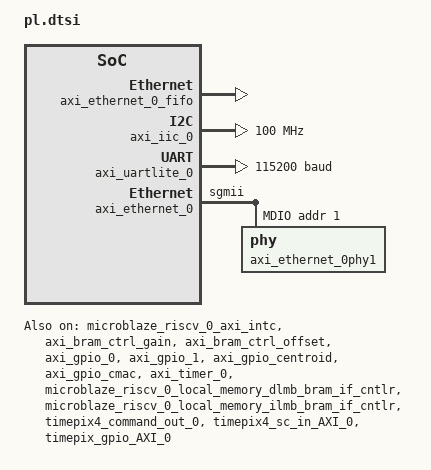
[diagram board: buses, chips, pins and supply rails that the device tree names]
/ {
	cpus_microblaze_riscv_0: cpus_microblaze_riscv@0 {
		#cpu-mask-cells = <1>;
		compatible = "cpus,cluster";
		#address-cells = <1>;
		#size-cells = <0>;
		microblaze_riscv_0: cpu@0 {
			xlnx,d-axi = <1>;
			xlnx,pmp-entries = <0>;
			xlnx,temporal-depth = <0>;
			xlnx,dcache-force-tag-lutram = <0>;
			reg = <0x0>;
			xlnx,interrupt-is-edge = <0>;
			xlnx,use-mmu = <0>;
			xlnx,dc-axi-mon = <0>;
			xlnx,debug-trace-async-reset = <0>;
			xlnx,part = "xcvu37p-fsvh2892-2l-e";
			xlnx,use-config-reset = <0>;
			xlnx,family = "virtexuplusHBM";
			xlnx,use-sleep = <0>;
			xlnx,d-lmb = <1>;
			xlnx,enable-discrete-ports = <0>;
			xlnx,debug-interface = <0>;
			xlnx,use-ext-brk = <0>;
			xlnx,debug-enabled = <1>;
			xlnx,daddr-size = <32>;
			xlnx,use-extended-fsl-instr = <0>;
			xlnx,branch-target-cache-size = <0>;
			bus-handle = <&amba_pl>;
			xlnx,pmp-addr0 = <0x0>;
			xlnx,pmp-addr1 = <0x0>;
			xlnx,pmp-addr2 = <0x0>;
			xlnx,pmp-addr3 = <0x0>;
			xlnx,pmp-addr4 = <0x0>;
			xlnx,edk-special = "microblaze_riscv";
			xlnx,use-dcache = <0>;
			xlnx,pmp-addr5 = <0x0>;
			xlnx,use-muldiv = <2>;
			xlnx,pmp-addr6 = <0x0>;
			xlnx,use-axi-dp-ext-addr = <0>;
			xlnx,pmp-addr7 = <0x0>;
			xlnx,pmp-addr8 = <0x0>;
			xlnx,pmp-addr9 = <0x0>;
			xlnx,i-axi = <0>;
			xlnx,icache-streams = <0>;
			xlnx,i-lmb-has-prot = <0>;
			xlnx,num-sync-ff-dbg-clk = <1>;
			xlnx,icache-byte-size = <4096>;
			xlnx,pmp-addr10 = <0x0>;
			d-cache-size = <4096>;
			xlnx,pmp-addr11 = <0x0>;
			xlnx,pmp-addr12 = <0x0>;
			xlnx,pmp-addr13 = <0x0>;
			xlnx,pmp-addr14 = <0x0>;
			xlnx,pmp-addr15 = <0x0>;
			xlnx,avoid-primitives = <0>;
			xlnx,pmp-addr16 = <0x0>;
			xlnx,pmp-addr17 = <0x0>;
			xlnx,pmp-addr18 = <0x0>;
			xlnx,pdaddr-size = <32>;
			xlnx,pmp-addr19 = <0x0>;
			xlnx,pmp-addr20 = <0x0>;
			xlnx,pmp-addr21 = <0x0>;
			xlnx,i-lmb = <1>;
			xlnx,pmp-addr22 = <0x0>;
			xlnx,lmb-data-size = <32>;
			xlnx,lockstep-select = <0>;
			xlnx,pmp-addr23 = <0x0>;
			timebase-frequency = <100000000>;
			xlnx,pmp-addr24 = <0x0>;
			xlnx,dcache-data-width = <0>;
			xlnx,icache-force-tag-lutram = <0>;
			xlnx,pmp-addr25 = <0x0>;
			xlnx,pmp-addr26 = <0x0>;
			xlnx,use-branch-target-cache = <0>;
			xlnx,pmp-addr27 = <0x0>;
			xlnx,number-of-pc-brk = <1>;
			xlnx,pmp-addr28 = <0x0>;
			xlnx,imprecise-exceptions = <0>;
			xlnx,pmp-addr29 = <0x0>;
			xlnx,pmp-addr30 = <0x0>;
			xlnx,pmp-addr31 = <0x0>;
			xlnx,pmp-addr32 = <0x0>;
			model = "microblaze_riscv,1.0";
			xlnx,pmp-addr33 = <0x0>;
			xlnx,pmp-addr34 = <0x0>;
			xlnx,pmp-addr35 = <0x0>;
			xlnx,pmp-addr36 = <0x0>;
			d-cache-highaddr = <0x3fffffff>;
			xlnx,optimization = <1>;
			xlnx,pmp-addr37 = <0x0>;
			xlnx,pmp-addr38 = <0x0>;
			xlnx,pmp-addr39 = <0x0>;
			xlnx,pmp-addr40 = <0x0>;
			xlnx,pmp-addr41 = <0x0>;
			xlnx,d-lmb-mon = <0>;
			xlnx,pmp-addr42 = <0x0>;
			xlnx,pmp-addr43 = <0x0>;
			xlnx,pmp-addr44 = <0x0>;
			xlnx,pmp-addr45 = <0x0>;
			xlnx,pmp-addr46 = <0x0>;
			xlnx,pmp-addr47 = <0x0>;
			xlnx,pmp-addr48 = <0x0>;
			xlnx,fault-tolerant = <0>;
			xlnx,pmp-addr49 = <0x0>;
			xlnx,pmp-addr50 = <0x0>;
			xlnx,pmp-addr51 = <0x0>;
			xlnx,pmp-enhancements = <0>;
			d-cache-line-size = <16>;
			xlnx,mmu-privileged-instr = <0>;
			xlnx,pmp-addr52 = <0x0>;
			clock-frequency = <100000000>;
			xlnx,pmp-addr53 = <0x0>;
			xlnx,pmp-addr54 = <0x0>;
			xlnx,pmp-addr55 = <0x0>;
			xlnx,i-lmb-protocol = <0>;
			xlnx,pmp-addr56 = <0x0>;
			xlnx,pmp-addr57 = <0x0>;
			xlnx,dp-axi-mon = <0>;
			xlnx,pmp-addr58 = <0x0>;
			xlnx,pmp-addr59 = <0x0>;
			xlnx,pmp-addr60 = <0x0>;
			xlnx,pmp-addr61 = <0x0>;
			xlnx,pmp-addr62 = <0x0>;
			xlnx,pmp-addr63 = <0x0>;
			xlnx,debug-external-trace = <0>;
			xlnx,addr-size = <32>;
			xlnx,debug-num-progbuf = <2>;
			xlnx,debug-event-counters = <0>;
			xlnx,edk-iptype = "PROCESSOR";
			xlnx,debug-latency-counters = <0>;
			xlnx,interconnect = <2>;
			xlnx,edge-is-positive = <1>;
			xlnx,use-icache = <0>;
			xlnx,async-wakeup = <3>;
			xlnx,s-axi = <0>;
			xlnx,use-ext-nm-brk = <0>;
			xlnx,ic-axi-mon = <0>;
			xlnx,archid = <0x1>;
			xlnx,num-sync-ff-clk-irq = <1>;
			xlnx,freq = <100000000>;
			xlnx,lockstep-master = <0>;
			xlnx,pmp-cfg0 = <0x0>;
			xlnx,pmp-cfg1 = <0x0>;
			xlnx,iaddr-size = <32>;
			xlnx,interrupt-mon = <0>;
			xlnx,pmp-cfg2 = <0x0>;
			xlnx,number-of-wr-addr-brk = <0>;
			xlnx,pmp-cfg3 = <0x0>;
			xlnx,pmp-cfg4 = <0x0>;
			xlnx,use-interrupt = <2>;
			xlnx,pmp-cfg5 = <0x0>;
			xlnx,async-interrupt = <1>;
			xlnx,pc-width = <20>;
			xlnx,pmp-cfg6 = <0x0>;
			xlnx,icache-victims = <0>;
			xlnx,pmp-cfg7 = <0x0>;
			xlnx,pmp-cfg8 = <0x0>;
			xlnx,pmp-cfg9 = <0x0>;
			xlnx,use-bitman-a = <0>;
			xlnx,use-bitman-b = <0>;
			xlnx,use-bitman-c = <0>;
			xlnx,i-lmb-mon = <0>;
			xlnx,dcache-byte-size = <4096>;
			xlnx,data-size = <32>;
			compatible = "xlnx,microblaze-riscv-1.0" , "xlnx,microblaze_riscv";
			xlnx,pmp-debug-inhibit = <0x0>;
			xlnx,use-sstc = <1>;
			xlnx,fsl-exception = <0>;
			xlnx,dcache-use-writeback = <0>;
			device_type = "cpu";
			xlnx,impid = <0x1>;
			xlnx,use-bitman-s = <0>;
			xlnx,base-vectors = <0x0>;
			xlnx,icache-line-len = <4>;
			xlnx,d-lmb-has-prot = <0>;
			xlnx,use-barrel = <1>;
			xlnx,misaligned-exceptions = <0>;
			xlnx,piaddr-size = <32>;
			xlnx,use-bitman = <0>;
			xlnx,dcache-line-len = <4>;
			xlnx,num-sync-ff-clk = <2>;
			xlnx,memory-ip-list = "microblaze_riscv_0_local_memory_ilmb_bram_if_cntlr_memory" , "microblaze_riscv_0_local_memory_dlmb_bram_if_cntlr_memory";
			xlnx,number-of-rd-addr-brk = <0>;
			xlnx,use-counters = <1>;
			xlnx,lockstep-slave = <0>;
			interrupt-handle = <&microblaze_riscv_0_axi_intc>;
			xlnx,pmp-cfg10 = <0x0>;
			xlnx,pmp-cfg11 = <0x0>;
			xlnx,debug-profile-size = <0>;
			xlnx,pmp-cfg12 = <0x0>;
			xlnx,pmp-cfg13 = <0x0>;
			xlnx,pmp-cfg14 = <0x0>;
			xlnx,pmp-cfg15 = <0x0>;
			xlnx,debug-counter-width = <64>;
			xlnx,icache-data-width = <0>;
			xlnx,ip-name = "microblaze_riscv";
			xlnx,ip-axi-mon = <0>;
			xlnx,d-lmb-protocol = <0>;
			xlnx,trace = <0>;
			xlnx,ill-instr-exception = <1>;
			xlnx,debug-trace-size = <8192>;
			xlnx,pmp-granularity = <3>;
			xlnx,num-sync-ff-dbg-trace-clk = <2>;
			xlnx,ecc-use-ce-exception = <0>;
			xlnx,num-sync-ff-clk-debug = <2>;
			xlnx,use-atomic = <0>;
			xlnx,g-template-list = <1>;
			xlnx,trap-enhancement = <0>;
			xlnx,hartid = <0x0>;
			xlnx,use-fpu = <0>;
			xlnx,use-non-secure = <0>;
			d-cache-baseaddr = <0x0>;
			xlnx,use-compression = <1>;
			xlnx,instr-size = <32>;
			xlnx,fsl-links = <0>;
			xlnx,dcache-victims = <0>;
			xlnx,pmp-read-only = <0x0>;
		};
	};
	clock: clocks {
		#address-cells = <1>;
		#size-cells = <0>;
		clk_cpu_0: clk_cpu@0 {
			compatible = "fixed-clock";
			reg = <0>;
			clock-frequency = <100000000>;
			clock-output-names = "clk_cpu";
			#clock-cells = <0>;
		};
		clk_bus_0: clk_bus_0@1 {
			compatible = "fixed-clock";
			reg = <1>;
			clock-frequency = <100000000>;
			clock-output-names = "clk_bus_0";
			#clock-cells = <0>;
		};
	};
	amba_pl: amba_pl {
		ranges;
		compatible = "simple-bus";
		#address-cells = <1>;
		#size-cells = <1>;
		microblaze_riscv_0_axi_intc: interrupt-controller@41200000 {
			#interrupt-cells = <2>;
			xlnx,sense-of-irq-edge-type = "Rising";
			xlnx,edk-special = "INTR_CTRL";
			xlnx,kind-of-intr = <0x0>;
			xlnx,kind-of-edge = <0xffffffff>;
			xlnx,irq-is-level = <1>;
			xlnx,has-ivr = <1>;
			compatible = "xlnx,axi-intc-4.1" , "xlnx,xps-intc-1.00.a";
			xlnx,disable-synchronizers = <1>;
			xlnx,kind-of-lvl = <0xffffffff>;
			xlnx,ivar-reset-value = <0x10>;
			xlnx,irq-active = <0x1>;
			xlnx,en-cascade-mode = <0>;
			xlnx,ip-name = "axi_intc";
			xlnx,has-ilr = <0>;
			reg = <0x41200000 0x10000>;
			xlnx,addr-width = <0x20>;
			xlnx,s-axi-aclk-freq-mhz = <100>;
			xlnx,num-sw-intr = <0>;
			xlnx,irq-connection = <0>;
			xlnx,num-intr-inputs = <0x4>;
			xlnx,has-sie = <1>;
			xlnx,enable-async = <0>;
			xlnx,has-cie = <1>;
			xlnx,num-sync-ff = <2>;
			xlnx,edk-iptype = "PERIPHERAL";
			xlnx,mb-clk-not-connected = <1>;
			xlnx,has-ipr = <1>;
			xlnx,sense-of-irq-level-type = "Active_High";
			xlnx,cascade-master = <0>;
			xlnx,processor-clk-freq-mhz = <100>;
			status = "okay";
			xlnx,is-fast = <0x1>;
			xlnx,has-fast = <1>;
			xlnx,ivar-rst-val = <0x10>;
			interrupt-controller;
			xlnx,async-intr = <0xfffffff4>;
			xlnx,name = "microblaze_riscv_0_axi_intc";
		};
		axi_bram_ctrl_gain: axi_bram_ctrl_gain@c0000000 {
			xlnx,protocol = "AXI4";
			xlnx,edk-special = "BRAM_CTRL";
			compatible = "xlnx,axi-bram-ctrl-4.1" , "xlnx,axi-bram-ctrl";
			xlnx,ecc-onoff-reset-value = <0>;
			xlnx,ecc-type = <0>;
			xlnx,rd-cmd-optimization = <0>;
			xlnx,memory-depth = <131072>;
			xlnx,use-ecc = <0>;
			xlnx,fault-inject = <0>;
			xlnx,ip-name = "axi_bram_ctrl";
			reg = <0xc0000000 0x80000>;
			xlnx,bmg-instance = "EXTERNAL";
			xlnx,s-axi-ctrl-addr-width = <32>;
			xlnx,read-latency = <1>;
			xlnx,id-width = <0>;
			xlnx,s-axi-supports-narrow-burst = <0>;
			xlnx,supports-narrow-burst = <0>;
			xlnx,single-port-bram = <1>;
			xlnx,ecc = <0>;
			xlnx,edk-iptype = "PERIPHERAL";
			status = "okay";
			xlnx,data-width = <32>;
			xlnx,bram-addr-width = <17>;
			xlnx,bram-inst-mode = "EXTERNAL";
			xlnx,s-axi-ctrl-data-width = <32>;
			xlnx,mem-depth = <131072>;
			xlnx,s-axi-id-width = <1>;
			xlnx,name = "axi_bram_ctrl_gain";
		};
		axi_bram_ctrl_offset: axi_bram_ctrl_offset@c2000000 {
			xlnx,protocol = "AXI4";
			xlnx,edk-special = "BRAM_CTRL";
			compatible = "xlnx,axi-bram-ctrl-4.1" , "xlnx,axi-bram-ctrl";
			xlnx,ecc-onoff-reset-value = <0>;
			xlnx,ecc-type = <0>;
			xlnx,rd-cmd-optimization = <0>;
			xlnx,memory-depth = <131072>;
			xlnx,use-ecc = <0>;
			xlnx,fault-inject = <0>;
			xlnx,ip-name = "axi_bram_ctrl";
			reg = <0xc2000000 0x80000>;
			xlnx,bmg-instance = "EXTERNAL";
			xlnx,s-axi-ctrl-addr-width = <32>;
			xlnx,read-latency = <1>;
			xlnx,id-width = <0>;
			xlnx,s-axi-supports-narrow-burst = <0>;
			xlnx,supports-narrow-burst = <0>;
			xlnx,single-port-bram = <1>;
			xlnx,ecc = <0>;
			xlnx,edk-iptype = "PERIPHERAL";
			status = "okay";
			xlnx,data-width = <32>;
			xlnx,bram-addr-width = <17>;
			xlnx,bram-inst-mode = "EXTERNAL";
			xlnx,s-axi-ctrl-data-width = <32>;
			xlnx,mem-depth = <131072>;
			xlnx,s-axi-id-width = <1>;
			xlnx,name = "axi_bram_ctrl_offset";
		};
		axi_ethernet_0_fifo: axi_fifo_mm_s@44a00000 {
			interrupts = < 1 2 >;
			xlnx,select-xpm = <0>;
			xlnx,axis-tuser-width = <4>;
			compatible = "xlnx,axi-fifo-mm-s-4.3" , "xlnx,axi-fifo-mm-s";
			xlnx,use-rx-data = <1>;
			xlnx,tx-cascade-height = <0>;
			xlnx,rx-has-ecc-err-inject = <0>;
			xlnx,axi-str-txc-protocol = "XIL_AXI_STREAM_ETH_CTRL";
			xlnx,use-tx-data = <1>;
			xlnx,tx-has-ecc-err-inject = <0>;
			xlnx,rx-fifo-depth = <4096>;
			interrupt-parent = <&microblaze_riscv_0_axi_intc>;
			xlnx,has-axis-tuser = <0>;
			xlnx,tx-fifo-depth = <4096>;
			xlnx,rx-fifo-pe-threshold = <10>;
			xlnx,data-interface-type = <0>;
			xlnx,ip-name = "axi_fifo_mm_s";
			xlnx,use-tx-ctrl = <1>;
			xlnx,rx-fifo-pf-threshold = <4000>;
			xlnx,axis-tid-width = <4>;
			reg = <0x44a00000 0x10000>;
			xlnx,tx-fifo-pe-threshold = <10>;
			xlnx,tx-fifo-pf-threshold = <4000>;
			xlnx,s-axi4-data-width = <32>;
			xlnx,has-axis-tstrb = <0>;
			xlnx,axi-str-rxd-protocol = "XIL_AXI_STREAM_ETH_DATA";
			xlnx,use-rx-cut-through = <0>;
			xlnx,axi-str-rxd-tdata-width = <32>;
			xlnx,axis-tdest-width = <4>;
			xlnx,edk-iptype = "PERIPHERAL";
			xlnx,has-axis-tkeep = <1>;
			xlnx,has-axis-tid = <0>;
			xlnx,axi-str-txc-tdata-width = <32>;
			xlnx,axi-str-txd-protocol = "XIL_AXI_STREAM_ETH_DATA";
			xlnx,use-tx-cut-through = <0>;
			xlnx,axi-str-txd-tdata-width = <32>;
			xlnx,rx-enable-ecc = <0>;
			status = "okay";
			xlnx,has-axis-tdest = <0>;
			interrupt-names = "interrupt";
			xlnx,tx-enable-ecc = <0>;
			xlnx,s-axi-id-width = <4>;
			xlnx,rx-cascade-height = <0>;
			xlnx,name = "axi_ethernet_0_fifo";
		};
		axi_gpio_0: gpio@40020000 {
			xlnx,gpio-board-interface = "led_8bits";
			compatible = "xlnx,axi-gpio-2.0" , "xlnx,xps-gpio-1.00.a";
			xlnx,all-outputs = <1>;
			#gpio-cells = <2>;
			xlnx,gpio-width = <8>;
			clock-frequency = <100000000>;
			xlnx,dout-default = <0x0>;
			xlnx,is-dual = <1>;
			xlnx,ip-name = "axi_gpio";
			xlnx,tri-default-2 = <0xffffffff>;
			reg = <0x40020000 0x10000>;
			xlnx,all-inputs-2 = <0>;
			clocks = <&clk_bus_0>;
			xlnx,all-outputs-2 = <1>;
			gpio-controller;
			xlnx,interrupt-present = <0>;
			xlnx,gpio2-board-interface = "Custom";
			xlnx,edk-iptype = "PERIPHERAL";
			xlnx,dout-default-2 = <0x0>;
			status = "okay";
			xlnx,gpio2-width = <4>;
			clock-names = "s_axi_aclk";
			xlnx,use-board-flow;
			xlnx,tri-default = <0xffffffff>;
			xlnx,name = "axi_gpio_0";
			xlnx,all-inputs = <0>;
		};
		axi_gpio_1: gpio@40010000 {
			xlnx,gpio-board-interface = "Custom";
			compatible = "xlnx,axi-gpio-2.0" , "xlnx,xps-gpio-1.00.a";
			xlnx,all-outputs = <0>;
			#gpio-cells = <2>;
			xlnx,gpio-width = <32>;
			clock-frequency = <100000000>;
			xlnx,dout-default = <0x0>;
			xlnx,is-dual = <1>;
			xlnx,ip-name = "axi_gpio";
			xlnx,tri-default-2 = <0xffffffff>;
			reg = <0x40010000 0x10000>;
			xlnx,all-inputs-2 = <0>;
			clocks = <&clk_bus_0>;
			xlnx,all-outputs-2 = <0>;
			gpio-controller;
			xlnx,interrupt-present = <0>;
			xlnx,gpio2-board-interface = "Custom";
			xlnx,edk-iptype = "PERIPHERAL";
			xlnx,dout-default-2 = <0x0>;
			status = "okay";
			xlnx,gpio2-width = <32>;
			clock-names = "s_axi_aclk";
			xlnx,tri-default = <0xffffffff>;
			xlnx,name = "axi_gpio_1";
			xlnx,all-inputs = <0>;
		};
		axi_gpio_centroid: gpio@40030000 {
			xlnx,gpio-board-interface = "Custom";
			compatible = "xlnx,axi-gpio-2.0" , "xlnx,xps-gpio-1.00.a";
			xlnx,all-outputs = <1>;
			#gpio-cells = <2>;
			xlnx,gpio-width = <32>;
			clock-frequency = <100000000>;
			xlnx,dout-default = <0x0>;
			xlnx,is-dual = <1>;
			xlnx,ip-name = "axi_gpio";
			xlnx,tri-default-2 = <0xffffffff>;
			reg = <0x40030000 0x10000>;
			xlnx,all-inputs-2 = <0>;
			clocks = <&clk_bus_0>;
			xlnx,all-outputs-2 = <1>;
			gpio-controller;
			xlnx,interrupt-present = <0>;
			xlnx,gpio2-board-interface = "Custom";
			xlnx,edk-iptype = "PERIPHERAL";
			xlnx,dout-default-2 = <0x0>;
			status = "okay";
			xlnx,gpio2-width = <32>;
			clock-names = "s_axi_aclk";
			xlnx,tri-default = <0xffffffff>;
			xlnx,name = "axi_gpio_centroid";
			xlnx,all-inputs = <0>;
		};
		axi_gpio_cmac: gpio@40000000 {
			xlnx,gpio-board-interface = "Custom";
			compatible = "xlnx,axi-gpio-2.0" , "xlnx,xps-gpio-1.00.a";
			xlnx,all-outputs = <0>;
			#gpio-cells = <2>;
			xlnx,gpio-width = <32>;
			clock-frequency = <100000000>;
			xlnx,dout-default = <0x0>;
			xlnx,is-dual = <0>;
			xlnx,ip-name = "axi_gpio";
			xlnx,tri-default-2 = <0xffffffff>;
			reg = <0x40000000 0x10000>;
			xlnx,all-inputs-2 = <0>;
			clocks = <&clk_bus_0>;
			xlnx,all-outputs-2 = <0>;
			gpio-controller;
			xlnx,interrupt-present = <0>;
			xlnx,gpio2-board-interface = "Custom";
			xlnx,edk-iptype = "PERIPHERAL";
			xlnx,dout-default-2 = <0x0>;
			status = "okay";
			xlnx,gpio2-width = <32>;
			clock-names = "s_axi_aclk";
			xlnx,tri-default = <0xffffffff>;
			xlnx,name = "axi_gpio_cmac";
			xlnx,all-inputs = <0>;
		};
		axi_iic_0: i2c@40800000 {
			xlnx,iic-freq-khz = <100>;
			compatible = "xlnx,axi-iic-2.1" , "xlnx,xps-iic-2.00.a";
			xlnx,scl-inertial-delay = <0>;
			clock-frequency = <100000000>;
			xlnx,ip-name = "axi_iic";
			xlnx,disable-setup-violation-check = <0>;
			reg = <0x40800000 0x10000>;
			clocks = <&clk_bus_0>;
			xlnx,gpo-width = <1>;
			xlnx,edk-iptype = "PERIPHERAL";
			xlnx,static-timing-reg-width = <0>;
			xlnx,sda-level = <1>;
			status = "okay";
			xlnx,ten-bit-adr = <0>;
			xlnx,default-value = <0x0>;
			xlnx,iic-board-interface = "Custom";
			xlnx,timing-reg-width = <32>;
			xlnx,iic-freq = <100000>;
			xlnx,smbus-pmbus-host = <0>;
			xlnx,name = "axi_iic_0";
			xlnx,axi-aclk-freq-mhz = <100>;
			xlnx,sda-inertial-delay = <0>;
		};
		axi_timer_0: timer@41c00000 {
			interrupts = < 0 2 >;
			compatible = "xlnx,axi-timer-2.0" , "xlnx,xps-timer-1.00.a";
			xlnx,gen1-assert = <1>;
			clock-frequency = <100000000>;
			xlnx,trig0-assert = <1>;
			interrupt-parent = <&microblaze_riscv_0_axi_intc>;
			xlnx,count-width = <32>;
			xlnx,ip-name = "axi_timer";
			xlnx,one-timer-only = <1>;
			reg = <0x41c00000 0x10000>;
			clocks = <&clk_bus_0>;
			xlnx,gen0-assert = <1>;
			xlnx,mode-64bit = <0>;
			xlnx,edk-iptype = "PERIPHERAL";
			status = "okay";
			xlnx,trig1-assert = <1>;
			xlnx,enable-timer2 = <0>;
			interrupt-names = "interrupt";
			xlnx,name = "axi_timer_0";
		};
		axi_uartlite_0: serial@40600000 {
			compatible = "xlnx,axi-uartlite-2.0" , "xlnx,xps-uartlite-1.00.a";
			clock-frequency = <100000000>;
			xlnx,uartlite-board-interface = "rs232_uart_0";
			xlnx,s-axi-aclk-freq-hz-d = <100>;
			xlnx,ip-name = "axi_uartlite";
			reg = <0x40600000 0x10000>;
			xlnx,baudrate = <115200>;
			clocks = <&clk_bus_0>;
			current-speed = <115200>;
			xlnx,use-parity = <0>;
			xlnx,edk-iptype = "PERIPHERAL";
			xlnx,odd-parity = <0>;
			status = "okay";
			xlnx,use-board-flow;
			xlnx,name = "axi_uartlite_0";
			xlnx,data-bits = <8>;
			xlnx,parity = "No_Parity";
		};
		microblaze_riscv_0_local_memory_dlmb_bram_if_cntlr: lmb_bram_if_cntlr@0 {
			xlnx,edk-special = "BRAM_CTRL";
			xlnx,write-access = <2>;
			compatible = "xlnx,lmb-bram-if-cntlr-4.0" , "xlnx,axi-bram-ctrl";
			xlnx,ecc-onoff-register = <0>;
			xlnx,ecc-onoff-reset-value = <1>;
			xlnx,s-axi-ctrl-protocol = "AXI4LITE";
			xlnx,mask = <0x40100000>;
			xlnx,mask1 = <0x800000>;
			xlnx,mask2 = <0x800000>;
			xlnx,fault-inject = <0>;
			xlnx,mask3 = <0x800000>;
			xlnx,ip-name = "lmb_bram_if_cntlr";
			xlnx,arbitration = <0>;
			xlnx,num-lmb = <1>;
			xlnx,mask4 = <0x800000>;
			reg = <0x00000000 0x100000>;
			xlnx,s-axi-ctrl-addr-width = <32>;
			xlnx,mask5 = <0x800000>;
			xlnx,ecc-status-registers = <0>;
			xlnx,prot-cfg = <0xff>;
			xlnx,mask6 = <0x800000>;
			xlnx,lmb-protocol = <0>;
			xlnx,ce-counter-width = <0>;
			xlnx,prot-cfg1 = <0xff>;
			xlnx,mask7 = <0x800000>;
			xlnx,ecc = <0>;
			xlnx,edk-iptype = "PERIPHERAL";
			xlnx,prot-cfg2 = <0xff>;
			xlnx,lmb-dwidth = <32>;
			xlnx,interconnect = <0>;
			xlnx,ce-failing-registers = <0>;
			xlnx,prot-cfg3 = <0xff>;
			xlnx,ue-failing-registers = <0>;
			xlnx,prot-cfg4 = <0xff>;
			xlnx,lmb-has-prot = <0>;
			status = "okay";
			xlnx,data-width = <32>;
			xlnx,prot-cfg5 = <0xff>;
			xlnx,s-axi-ctrl-data-width = <32>;
			xlnx,prot-cfg6 = <0xff>;
			xlnx,bram-awidth = <32>;
			xlnx,prot-cfg7 = <0xff>;
			xlnx,lmb-awidth = <32>;
			xlnx,name = "microblaze_riscv_0_local_memory_dlmb_bram_if_cntlr";
		};
		microblaze_riscv_0_local_memory_ilmb_bram_if_cntlr: microblaze_riscv_0_local_memory_ilmb_bram_if_cntlr@0 {
			xlnx,edk-special = "BRAM_CTRL";
			xlnx,write-access = <2>;
			compatible = "xlnx,lmb-bram-if-cntlr-4.0" , "xlnx,axi-bram-ctrl";
			xlnx,ecc-onoff-register = <0>;
			xlnx,ecc-onoff-reset-value = <1>;
			xlnx,s-axi-ctrl-protocol = "AXI4LITE";
			xlnx,mask = <0x0>;
			xlnx,mask1 = <0x800000>;
			xlnx,mask2 = <0x800000>;
			xlnx,fault-inject = <0>;
			xlnx,mask3 = <0x800000>;
			xlnx,ip-name = "lmb_bram_if_cntlr";
			xlnx,arbitration = <0>;
			xlnx,num-lmb = <1>;
			xlnx,mask4 = <0x800000>;
			reg = <0x00000000 0x100000>;
			xlnx,s-axi-ctrl-addr-width = <32>;
			xlnx,mask5 = <0x800000>;
			xlnx,ecc-status-registers = <0>;
			xlnx,prot-cfg = <0xff>;
			xlnx,mask6 = <0x800000>;
			xlnx,lmb-protocol = <0>;
			xlnx,ce-counter-width = <0>;
			xlnx,prot-cfg1 = <0xff>;
			xlnx,mask7 = <0x800000>;
			xlnx,ecc = <0>;
			xlnx,edk-iptype = "PERIPHERAL";
			xlnx,prot-cfg2 = <0xff>;
			xlnx,lmb-dwidth = <32>;
			xlnx,interconnect = <0>;
			xlnx,ce-failing-registers = <0>;
			xlnx,prot-cfg3 = <0xff>;
			xlnx,ue-failing-registers = <0>;
			xlnx,prot-cfg4 = <0xff>;
			xlnx,lmb-has-prot = <0>;
			status = "okay";
			xlnx,prot-cfg5 = <0xff>;
			xlnx,s-axi-ctrl-data-width = <32>;
			xlnx,prot-cfg6 = <0xff>;
			xlnx,bram-awidth = <32>;
			xlnx,prot-cfg7 = <0xff>;
			xlnx,lmb-awidth = <32>;
			xlnx,name = "microblaze_riscv_0_local_memory_ilmb_bram_if_cntlr";
		};
		timepix4_command_out_0: timepix4_command_out_AXI@100000 {
			compatible = "xlnx,timepix4-command-out-AXI-1.0";
			status = "okay";
			xlnx,ip-name = "timepix4_command_out_AXI";
			xlnx,edk-iptype = "PERIPHERAL";
			reg = <0x00100000 0x1000>;
			xlnx,name = "timepix4_command_out_0";
		};
		timepix4_sc_in_AXI_0: timepix4_sc_in_AXI@110000 {
			interrupt-parent = <&microblaze_riscv_0_axi_intc>;
			interrupts = < 3 2 >;
			compatible = "xlnx,timepix4-sc-in-AXI-1.0";
			status = "okay";
			xlnx,ip-name = "timepix4_sc_in_AXI";
			interrupt-names = "sc_irq";
			xlnx,edk-iptype = "PERIPHERAL";
			reg = <0x00110000 0x1000>;
			xlnx,name = "timepix4_sc_in_AXI_0";
		};
		timepix_gpio_AXI_0: timepix_gpio_AXI@101000 {
			compatible = "xlnx,timepix-gpio-AXI-1.0";
			status = "okay";
			xlnx,ip-name = "timepix_gpio_AXI";
			xlnx,edk-iptype = "PERIPHERAL";
			reg = <0x00101000 0x1000>;
			xlnx,name = "timepix_gpio_AXI_0";
		};
		axi_ethernet_0: ethernet@40c00000 {
			xlnx,speed-1-2p5 = <1000>;
			xlnx,txlane1-placement = "0";
			xlnx,ip-name = "axi_ethernet";
			xlnx,is-gt-wiz-old = <0>;
			reg = <0x40c00000 0x40000>;
			pcs-handle = <&axi_ethernet_0phy1>;
			xlnx,include-io;
			xlnx,rxmem = <0x1000>;
			xlnx,tx-in-upper-nibble;
			xlnx,axisclkrate = <0>;
			xlnx,txmem = "0";
			xlnx,mdio-board-interface = "0";
			xlnx,phyaddr = <0x1>;
			xlnx,enable-lvds;
			xlnx,supportlevel = <0>;
			local-mac-address = [ 00 0a 23 00 00 00 ];
			xlnx,diffclk-board-interface = "0";
			xlnx,frame-filter;
			axistream-connected = <&axi_ethernet_0_fifo>;
			interrupt-names = "interrupt";
			xlnx,phyrst-board-interface-dummy-port = "0";
			compatible = "xlnx,axi-ethernet-8.0" , "xlnx,axi-ethernet-1.00.a" , "xlnx,axi-ethernet-1.00.a";
			xlnx,gt-type = "0";
			xlnx,drpclkrate = <0>;
			clock-frequency = <>;
			axistream-control-connected = <&axi_ethernet_0_fifo>;
			interrupt-parent = <&microblaze_riscv_0_axi_intc>;
			managed = "in-band-status";
			xlnx,versal-gt-board-flow = <0>;
			xlnx,switch-x-sgmii;
			max-speed = <1000>;
			status = "okay";
			xlnx,timer-format = <0>;
			xlnx,use-board-flow;
			xlnx,statistics-width = "0";
			xlnx,name = "axi_ethernet_0";
			interrupts = < 2 2 >;
			xlnx,instantiatebitslice0;
			xlnx,gtrefclksrc = "0";
			xlnx,rxcsum = <0x0>;
			xlnx,statistics-counters;
			xlnx,edk-iptype = "0";
			xlnx,gtrefclkrate = <0>;
			xlnx,lvdsclkrate = <0>;
			xlnx,number-of-table-entries = <0>;
			xlnx,rxlane0-placement = "0";
			xlnx,timer-clk-period = <0>;
			xlnx,ethernet-board-interface = "0";
			xlnx,txlane0-placement = "0";
			xlnx,gtlocation = "0";
			phy-mode = "sgmii";
			xlnx,gt-settings = <0>;
			xlnx,clockselection = "0";
			xlnx,processor-mode;
			xlnx,txcsum = <0x0>;
			xlnx,phyrst-board-interface = "0";
			xlnx,axiliteclkrate = <0>;
			xlnx,rxlane1-placement = "0";
			axi_ethernet_0_mdio: mdio {
				#address-cells = <1>;
				#size-cells = <0>;
				axi_ethernet_0phy1: phy@1 {
					device_type = "ethernet-phy";
					reg = <1>;
				};
			};
		};
	};
};
